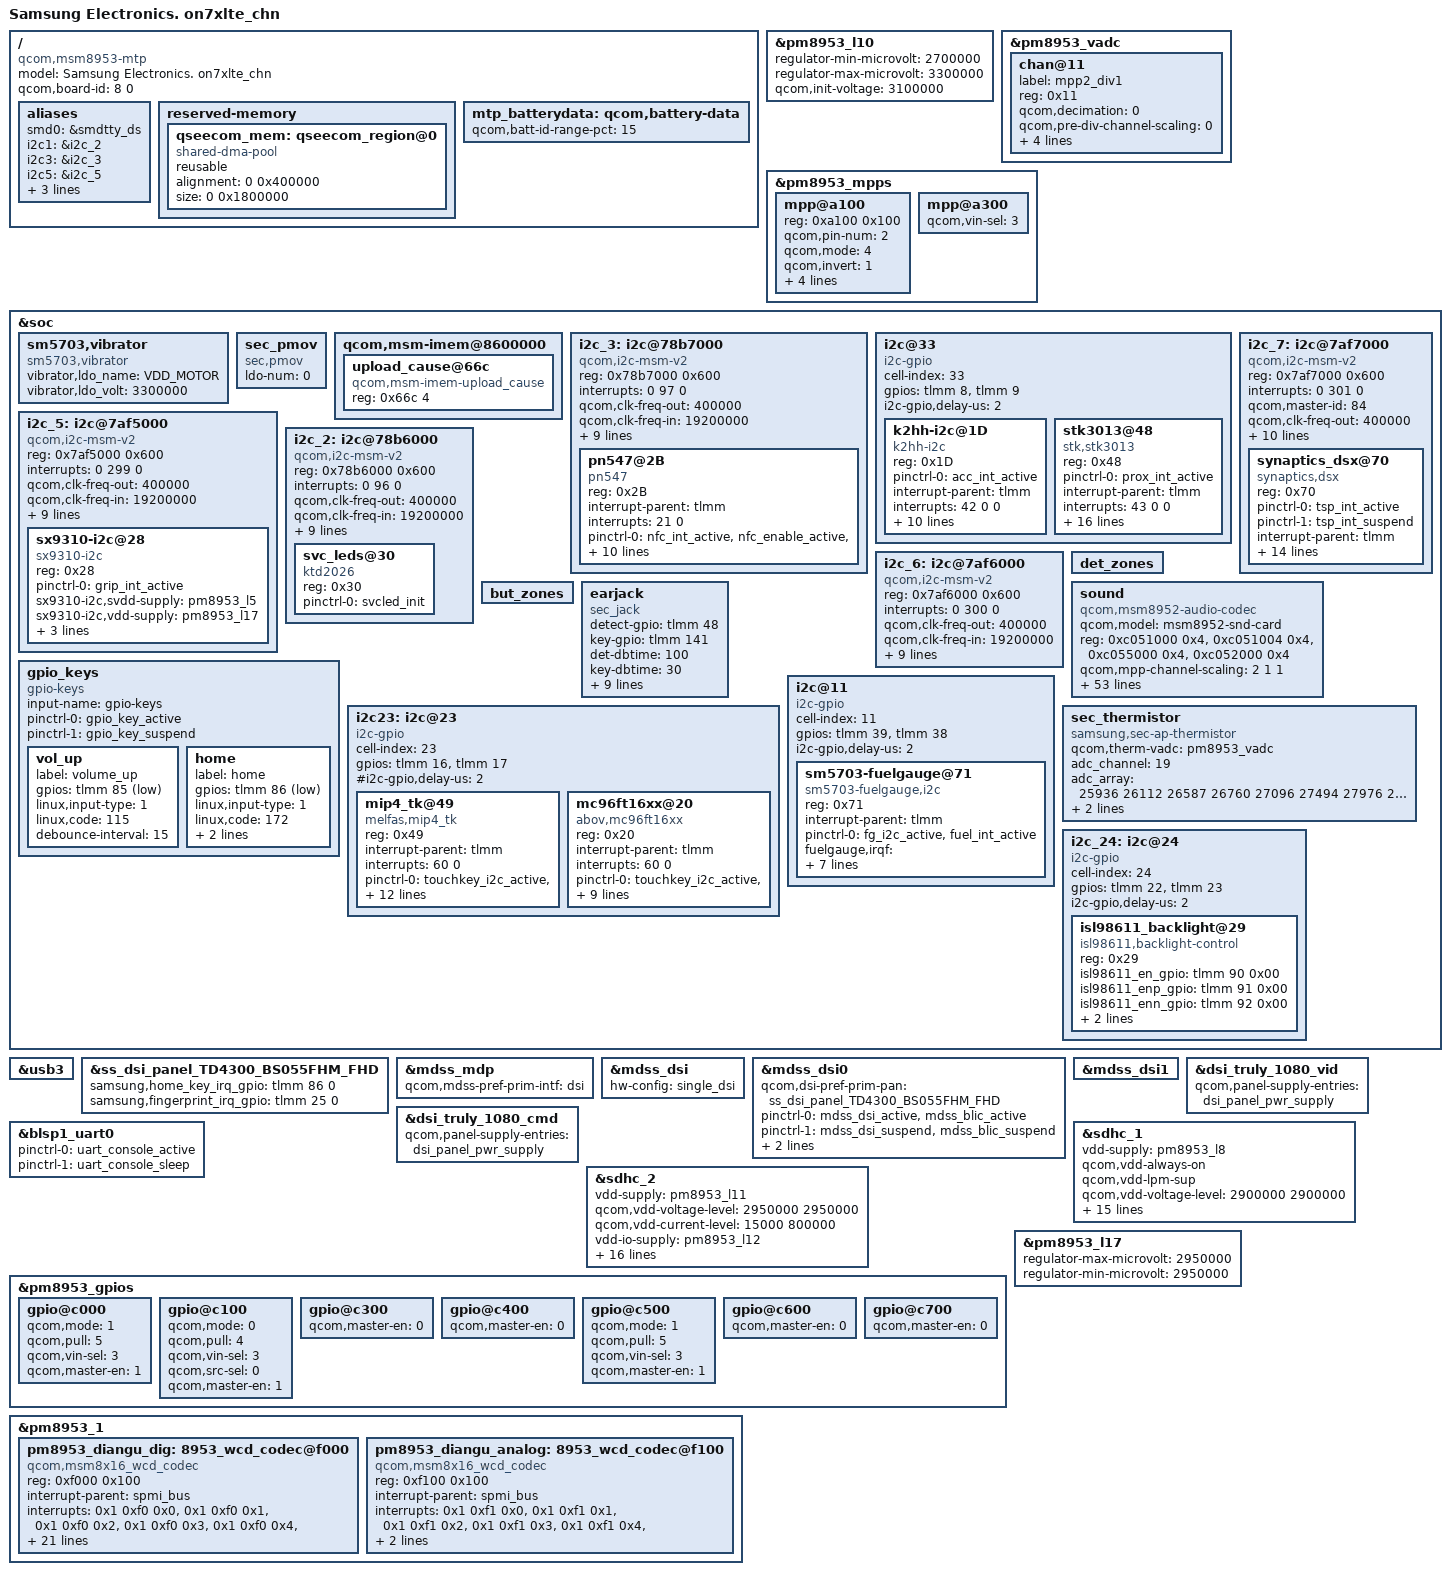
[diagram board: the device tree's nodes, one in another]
/*
 * Copyright (c) 2015, The Linux Foundation. All rights reserved.
 *
 * This program is free software; you can redistribute it and/or modify
 * it under the terms of the GNU General Public License version 2 and
 * only version 2 as published by the Free Software Foundation.
 *
 * This program is distributed in the hope that it will be useful,
 * but WITHOUT ANY WARRANTY; without even the implied warranty of
 * MERCHANTABILITY or FITNESS FOR A PARTICULAR PURPOSE.  See the
 * GNU General Public License for more details.
 */

/dts-v1/;

#include "../../qcom/msm8953.dtsi"
#include "msm-sec-audio.dtsi"
#include "msm8953-sec-common.dtsi"
#include "msm8953-sec-on7xlte_chn-pinctrl-r00.dtsi"
#include "msm8953-sec-on7xlte_chn-battery-r00.dtsi"
#include "msm8953-sec-on7xlte-chn-fingerprint-sensor_00.dtsi"
#include "msm8953-camera-sensor-on7-chn-r00.dtsi"
#include "msm8953-on7xlte-sm5703.dtsi"
#include "../../../../../../drivers/video/msm/mdss/samsung/TD4300_BS055FHM/dsi_panel_TD4300_BS055FHM_fhd_video.dtsi"
#include "../../../../../../drivers/video/msm/mdss/samsung/PBA_BOOTING_HD/dsi_panel_PBA_BOOTING_hd_video.dtsi"
/ {
	model = "Samsung Electronics. on7xlte_chn";
	compatible = "qcom,msm8953-mtp", "qcom,msm8953", "qcom,mtp";
	qcom,board-id= <8 0>;
	aliases {
		/delete-property/ spi3;
		/delete-property/ i2c2;
		smd0 = &smdtty_ds;
		i2c1 = &i2c_2; //SVC i2C
		i2c3 = &i2c_3; //NFC i2c
		i2c5 = &i2c_5; //Grip i2c
		i2c6 = &i2c_6; //LCD_BL i2c
		i2c7 = &i2c_7; //TSP i2c
		i2c8 = &i2c_8;
	};

	reserved-memory {
		/delete-node/ qseecom_region@0;
		qseecom_mem: qseecom_region@0 {
			compatible = "shared-dma-pool";
			reusable;
			alignment = <0 0x400000>;
			size = <0 0x1800000>;
		};
	};
};

&pm8953_l10 {
	status = "okay";
	regulator-min-microvolt = <2700000>;
	regulator-max-microvolt = <3300000>;
	qcom,init-voltage = <3100000>;
};

&pm8953_vadc {
	chan@11 {
		label = "mpp2_div1";
		reg = <0x11>;
		qcom,decimation = <0>;
		qcom,pre-div-channel-scaling = <0>;
		qcom,calibration-type = "absolute";
		qcom,scale-function = <0>;
		qcom,hw-settle-time = <5>;
		qcom,fast-avg-setup = <0>;
	};
};

&pm8953_mpps {
	mpp@a100 {
		reg = <0xa100 0x100>;
		qcom,pin-num = <2>;
		status = "okay";
		qcom,mode = <4>; /* AIN input */
		qcom,invert = <1>; /* Enable MPP */
		qcom,ain-route = <1>; /* AMUX 6 */
		qcom,master-en = <1>;
		qcom,src-sel = <0>; /* Function constant */
		qcom,vin-sel = <3>;
	};
	mpp@a300 {
		qcom,vin-sel = <3>;
		status = "okay";
	};
};

&soc {
	sm5703,vibrator {
		compatible = "sm5703,vibrator";
		vibrator,ldo_name = "VDD_MOTOR";
		vibrator,ldo_volt = <3300000>;
		status = "ok";
	};
	sec_pmov {
		compatible = "sec,pmov";

		/* pinctrl-names = "default";
		pinctrl-0 = <&nc_gpio_default>; */

		ldo-num = <0>;
		/*ldo0-supply = <&pm8953_l17>;
		 ldo1-supply = <&pm8953_lx>; */
	};

	qcom,msm-imem@8600000 {
		upload_cause@66c { /* CONFIG_SEC_DEBUG */
			compatible = "qcom,msm-imem-upload_cause";
			reg = <0x66c 4>;
		};
	};

	i2c_3: i2c@78b7000 { /* BLSP1 QUP3 */
		compatible = "qcom,i2c-msm-v2";
		#address-cells = <1>;
		#size-cells = <0>;
		reg-names = "qup_phys_addr";
		reg = <0x78b7000 0x600>;
		interrupt-names = "qup_irq";
		interrupts = <0 97 0>;
		qcom,clk-freq-out = <400000>;
		qcom,clk-freq-in  = <19200000>;
		clock-names = "iface_clk", "core_clk";
		clocks = <&clock_gcc clk_gcc_blsp1_ahb_clk>,
			<&clock_gcc clk_gcc_blsp1_qup3_i2c_apps_clk>;

		pinctrl-names = "i2c_active", "i2c_sleep";
		pinctrl-0 = <&i2c_3_active>;
		pinctrl-1 = <&i2c_3_sleep>;
		qcom,noise-rjct-scl = <0>;
		qcom,noise-rjct-sda = <0>;
		qcom,master-id = <86>;
		dmas = <&dma_blsp1 8 64 0x20000020 0x20>,
			<&dma_blsp1 9 32 0x20000020 0x20>;
		dma-names = "tx", "rx";
		status = "okay";

		pn547@2B {
			compatible = "pn547";
			reg = <0x2B>;
			interrupt-parent = <&tlmm>;
			interrupts = <21 0>;
			pinctrl-names = "default","sleep";
			pinctrl-0 = <&nfc_int_active &nfc_enable_active &nfc_pwr_req_active>;
			pinctrl-1 = <&nfc_int_suspend &nfc_enable_suspend>;
			pn547,ven-gpio = <&tlmm 93 0x0>;
			pn547,firm-gpio = <&tlmm 95 0x0>;
			pn547,irq-gpio = <&tlmm 21 0x00>;
			pn547,pwr_req = <&tlmm 97 0x00>;
			pn547,pvdd-gpio = <&tlmm 96 0x01>;
			/*pn547,clk_req-gpio = <&pm8950_gpios 2 0x00>;*/

			pn547,nfc_pm_clk;
			qcom,clk-src="BBCLK2";
			clocks = <&clock_gcc clk_bb_clk2_pin>;
			clock-names = "rf_clk";
		};
	};

	i2c@33 {
		cell-index = <33>;
		compatible = "i2c-gpio";
		gpios = <&tlmm 8 0	/* sda */
			&tlmm 9 0	/* scl */
			>;
		i2c-gpio,delay-us = <2>;
		#address-cells = <1>;
		#size-cells = <0>;

		k2hh-i2c@1D {
			compatible = "k2hh-i2c";
			reg = <0x1D>;
			pinctrl-names = "default";
			pinctrl-0 = <&acc_int_active>;
			interrupt-parent = <&tlmm>;
			interrupts = <42 0 0>;
			k2hh,irq_gpio = <&tlmm 42 0>;
			k2hh,vio-supply = <&pm8953_l5>;
			k2hh,axis_map_x = <0>;
			k2hh,axis_map_y = <1>;
			k2hh,axis_map_z = <2>;
			k2hh,negate_x = <1>;
			k2hh,negate_y = <0>;
			k2hh,negate_z = <0>;
			k2hh,poll_interval = <100>;
			k2hh,min_interval = <2>;
		};

		stk3013@48 {
			compatible = "stk,stk3013";
			reg = <0x48>;
			pinctrl-names = "default";
			pinctrl-0 = <&prox_int_active>;
			interrupt-parent =  <&tlmm>;
			interrupts = <43 0 0>;
			stk,vdd-supply = <&pm8953_l17>;
			stk,vio-supply = <&pm8953_l5>;
			stk,irq-gpio = <&tlmm 43 0>;
			stk,state-reg = <0x2d>;
			stk,psctrl-reg = <0x70>;
			stk,alsctrl-reg = <0x2A>;
			stk,ledctrl-reg = <0xF8>;
			stk,wait-reg = <0x03>;
			stk,ps-thd-h = <20>;
			stk,ps-thd-l = <13>;
			stk,ps-cancel-thd-h = <9>;
			stk,ps-cancel-thd-l = <6>;
			stk,ps-cal-skip-adc = <8>;
			stk,ps-cal-fail-adc = <17>;
			stk,ps-default-offset = <0>;
			stk,transmittance = <500>;
		};

	};

	i2c_5: i2c@7af5000 { /* BLSP2 QUP1 */
		compatible = "qcom,i2c-msm-v2";
		#address-cells = <1>;
		#size-cells = <0>;
		reg-names = "qup_phys_addr";
		reg = <0x7af5000 0x600>;
		interrupt-names = "qup_irq";
		interrupts = <0 299 0>;
		qcom,clk-freq-out = <400000>;
		qcom,clk-freq-in  = <19200000>;
		clock-names = "iface_clk", "core_clk";
		clocks = <&clock_gcc clk_gcc_blsp2_ahb_clk>,
			<&clock_gcc clk_gcc_blsp2_qup1_i2c_apps_clk>;

		pinctrl-names = "i2c_active", "i2c_sleep";
		pinctrl-0 = <&i2c_5_active>;
		pinctrl-1 = <&i2c_5_sleep>;
		qcom,noise-rjct-scl = <0>;
		qcom,noise-rjct-sda = <0>;
		qcom,master-id = <84>;
		dmas = <&dma_blsp2 4 64 0x20000020 0x20>,
			<&dma_blsp2 5 32 0x20000020 0x20>;
		dma-names = "tx", "rx";
		sx9310-i2c@28 {
			compatible = "sx9310-i2c";
			reg = <0x28>;
			pinctrl-names = "grip_int_active","grip_int_suspend";
			pinctrl-0 = <&grip_int_active>;
			sx9310-i2c,svdd-supply = <&pm8953_l5>;
			sx9310-i2c,vdd-supply = <&pm8953_l17>;
			interrupt-parent = <&tlmm>;
			interrupts = <44 0>;
			sx9310-i2c,nirq-gpio = <&tlmm 44 0x00>;
		};

	};

	i2c_7: i2c@7af7000 { /* BLSP2 QUP3 */
		compatible = "qcom,i2c-msm-v2";
		#address-cells = <1>;
		#size-cells = <0>;
		reg-names = "qup_phys_addr";
		reg = <0x7af7000 0x600>;
		interrupt-names = "qup_irq";
		interrupts = <0 301 0>;
		qcom,master-id = <84>;
		qcom,clk-freq-out = <400000>;
		qcom,clk-freq-in  = <19200000>;
		clock-names = "iface_clk", "core_clk";
		clocks = <&clock_gcc clk_gcc_blsp2_ahb_clk>,
			<&clock_gcc clk_gcc_blsp2_qup3_i2c_apps_clk>;
		pinctrl-names = "i2c_active", "i2c_sleep";
		pinctrl-0 = <&i2c_7_active>;
		pinctrl-1 = <&i2c_7_suspend>;
		qcom,noise-rjct-scl = <0>;
		qcom,noise-rjct-sda = <0>;
		qcom,disable-dma;
		dmas = <&dma_blsp2 8 64 0x20000020 0x20>,
			<&dma_blsp2 9 32 0x20000020 0x20>;
		dma-names = "tx", "rx";
	};

	/delete-node/i2c@78b6000;

	i2c_2: i2c@78b6000 { /* BLSP1 QUP2 */
		compatible = "qcom,i2c-msm-v2";
		#address-cells = <1>;
		#size-cells = <0>;
		reg-names = "qup_phys_addr";
		reg = <0x78b6000 0x600>;
		interrupt-names = "qup_irq";
		interrupts = <0 96 0>;
		qcom,clk-freq-out = <400000>;
		qcom,clk-freq-in  = <19200000>;
		clock-names = "iface_clk", "core_clk";
		clocks = <&clock_gcc clk_gcc_blsp1_ahb_clk>,
			<&clock_gcc clk_gcc_blsp1_qup2_i2c_apps_clk>;

		pinctrl-names = "i2c_active", "i2c_sleep";
		pinctrl-0 = <&i2c_2_active>;
		pinctrl-1 = <&i2c_2_sleep>;
		qcom,noise-rjct-scl = <0>;
		qcom,noise-rjct-sda = <0>;
		qcom,master-id = <86>;
		dmas = <&dma_blsp1 6 64 0x20000020 0x20>,
			<&dma_blsp1 7 32 0x20000020 0x20>;
		dma-names = "tx", "rx";
		svc_leds@30{
			compatible = "ktd2026";
			reg = <0x30>;
			pinctrl-names = "default";
			pinctrl-0 = <&svcled_init>;
		};

	};

	i2c_6: i2c@7af6000 { /* BLSP2 QUP2 */
		compatible = "qcom,i2c-msm-v2";
		#address-cells = <1>;
		#size-cells = <0>;
		reg-names = "qup_phys_addr";
		reg = <0x7af6000 0x600>;
		interrupt-names = "qup_irq";
		interrupts = <0 300 0>;
		qcom,clk-freq-out = <400000>;
		qcom,clk-freq-in  = <19200000>;
		clock-names = "iface_clk", "core_clk";
		clocks = <&clock_gcc clk_gcc_blsp2_ahb_clk>,
			<&clock_gcc clk_gcc_blsp2_qup2_i2c_apps_clk>;
		pinctrl-names = "i2c_active", "i2c_sleep";
		pinctrl-0 = <&i2c_6_active>;
		pinctrl-1 = <&i2c_6_sleep>;
		qcom,noise-rjct-scl = <0>;
		qcom,noise-rjct-sda = <0>;
		qcom,master-id = <84>;
		dmas = <&dma_blsp2 6 64 0x20000020 0x20>,
			<&dma_blsp2 7 32 0x20000020 0x20>;
		dma-names = "tx", "rx";
	};

	det_zones: det_zones {
		#list-det-cells = <4>;
	};

	but_zones: but_zones {
		#list-but-cells = <3>;
	};

	earjack {
		compatible = "sec_jack";
		detect-gpio = <&tlmm 48 0x0>;
		key-gpio = <&tlmm 141 0x0>;
		det-dbtime = <100>;
		key-dbtime = <30>;

		det-zones-list = <&det_zones 0 10000 10 2>,
				 <&det_zones 900 10000 10 2>,
				 <&det_zones 901 10000 10 1>,
				 <&det_zones 9999 10000 10 1>;
		but-zones-list = <&but_zones 226 0 186>, /* KEY_MEDIA:226 */
				 <&but_zones 582 187 229>, /* KEY_VOICECOMMAND:582 */
				 <&but_zones 115 230 343>, /* KEY_VOLUMEUP:115 */
				 <&but_zones 114 344 999>; /* KEY_VOLUMEDOWN:114 */

		pinctrl-names = "earjack_gpio_active",
				"earjack_gpio_suspend";
		pinctrl-0 = <&earjack_det_act &earjack_switch_act>;
		pinctrl-1 = <&earjack_det_sus &earjack_switch_sus>;
	};

	sound {
		compatible = "qcom,msm8952-audio-codec";
		qcom,model = "msm8952-snd-card";
		reg = <0xc051000 0x4>,
		      <0xc051004 0x4>,
		      <0xc055000 0x4>,
		      <0xc052000 0x4>;
		reg-names = "csr_gp_io_mux_mic_ctl",
			    "csr_gp_io_mux_spkr_ctl",
			    "csr_gp_io_lpaif_pri_pcm_pri_mode_muxsel",
			    "csr_gp_io_mux_quin_ctl";

		qcom,mpp-channel-scaling = <2 1 1>;
		qcom,earjack-read-vadc = <&pm8953_vadc>;
		qcom,msm-micbias1-ext-cap;
		qcom,msm-micbias2-ext-cap;
		qcom,msm-ext-pa = "primary";
		qcom,msm-mclk-freq = <9600000>;
		qcom,codec_ear_bias = <0>;
		qcom,msm-hs-micbias-type = "internal";
		qcom,audio-routing =
			"RX_BIAS", "MCLK",
			"SPK_RX_BIAS", "MCLK",
			"INT_LDO_H", "MCLK",
			"MIC BIAS External", "Handset Mic",
			"MIC BIAS External", "Secondary Mic",
			"AMIC1", "MIC BIAS External",
			"AMIC2", "Headset Mic",
			"AMIC3", "MIC BIAS External";
		qcom,msm-gpios =
			"pri_i2s",
			"comp_gpio";
		qcom,pinctrl-names =
			"all_off",
			"pri_i2s_act",
			"comp_gpio_act",
			"pri_i2s_comp_gpio_act";
		pinctrl-names =
			"all_off",
			"pri_i2s_act",
			"comp_gpio_act",
			"pri_i2s_comp_gpio_act";
		pinctrl-0 = <&cdc_pdm_lines_sus &cdc_pdm_comp_lines_sus &cdc_pdm_lines_2_sus >;
		pinctrl-1 = <&cdc_pdm_lines_act &cdc_pdm_comp_lines_sus &cdc_pdm_lines_2_act >;
		pinctrl-2 = <&cdc_pdm_lines_sus &cdc_pdm_comp_lines_act &cdc_pdm_lines_2_sus >;
		pinctrl-3 = <&cdc_pdm_lines_act &cdc_pdm_comp_lines_act &cdc_pdm_lines_2_act >;
		asoc-platform = <&pcm0>, <&pcm1>, <&pcm2>, <&voip>, <&voice>,
				<&loopback>, <&compress>, <&hostless>,
				<&afe>, <&lsm>, <&routing>, <&lpa>;
		asoc-platform-names = "msm-pcm-dsp.0", "msm-pcm-dsp.1",
				"msm-pcm-dsp.2", "msm-voip-dsp",
				"msm-pcm-voice", "msm-pcm-loopback",
				"msm-compress-dsp", "msm-pcm-hostless",
				"msm-pcm-afe", "msm-lsm-client",
				"msm-pcm-routing", "msm-pcm-lpa";
		asoc-cpu = <&dai_pri_auxpcm>,
				<&dai_mi2s0>, <&dai_mi2s1>,
				<&dai_mi2s2>, <&dai_mi2s3>,
				<&dai_mi2s5>, <&dai_mi2s6>,
				<&bt_sco_rx>, <&bt_sco_tx>,
				<&int_fm_rx>, <&int_fm_tx>,
				<&afe_pcm_rx>, <&afe_pcm_tx>,
				<&afe_proxy_rx>, <&afe_proxy_tx>,
				<&incall_record_rx>, <&incall_record_tx>,
				<&incall_music_rx>, <&incall_music_2_rx>;
		asoc-cpu-names = "msm-dai-q6-auxpcm.1",
				"msm-dai-q6-mi2s.0", "msm-dai-q6-mi2s.1",
				"msm-dai-q6-mi2s.2", "msm-dai-q6-mi2s.3",
				"msm-dai-q6-mi2s.5", "msm-dai-q6-mi2s.6",
				"msm-dai-q6-dev.12288", "msm-dai-q6-dev.12289",
				"msm-dai-q6-dev.12292", "msm-dai-q6-dev.12293",
				"msm-dai-q6-dev.224", "msm-dai-q6-dev.225",
				"msm-dai-q6-dev.241", "msm-dai-q6-dev.240",
				"msm-dai-q6-dev.32771", "msm-dai-q6-dev.32772",
				"msm-dai-q6-dev.32773", "msm-dai-q6-dev.32770";
		asoc-codec = <&stub_codec>, <&pm8953_diangu_dig>;
		asoc-codec-names = "msm-stub-codec.1", "cajon_codec";
	};

	gpio_keys {
		compatible = "gpio-keys";
		input-name = "gpio-keys";
		pinctrl-names = "tlmm_gpio_key_active","tlmm_gpio_key_suspend";
		pinctrl-0 = <&gpio_key_active>;
		pinctrl-1 = <&gpio_key_suspend>;

		vol_up {
			label = "volume_up";
			gpios = <&tlmm 85 0x1>;
			linux,input-type = <1>;
			linux,code = <115>;
			debounce-interval = <15>;
		};

		home {
			label = "home";
			gpios = <&tlmm 86 0x1>;
			linux,input-type = <1>;
			linux,code = <172>;
			gpio-key,wakeup;
			debounce-interval = <15>;
		};
	};

	i2c23: i2c@23 { /* SW I2C */
		cell-index = <23>;
		compatible = "i2c-gpio";
		gpios = <&tlmm 16 0 /* sda */
			&tlmm 17 0 /* scl */
		>;
		#i2c-gpio,delay-us = <2>;
		#address-cells = <1>;
		#size-cells = <0>;

		mip4_tk@49{
			compatible = "melfas,mip4_tk";
			reg = <0x49>;
			interrupt-parent = <&tlmm>;
			interrupts = <60 0>;
			pinctrl-names = "touchkey_active", "touchkey_suspend";
			pinctrl-0 = <&touchkey_i2c_active &touchkey_int_active>;
			pinctrl-1 = <&touchkey_i2c_suspend &touchkey_int_suspend>;
			mip4_tk,keynum = <2>;
			mip4_tk,keycode = <254 158>;
			mip4_tk,sda-gpio = <&tlmm 16 0>;
			mip4_tk,scl-gpio = <&tlmm 17 0>;
			mip4_tk,irq-gpio = <&tlmm 60 0>;
			mip4_tk,pwr-reg-name = "pwr";
			//mip4_tk,bus-reg-name = "bus";
			//bus-supply = <&pm8953_l6>;
			pwr-supply = <&pm8953_l10>;
			mip4_tk,firmware-name = "tk_melfas/mhs204_on7xlte.fw";
		};

		mc96ft16xx@20{
			compatible = "abov,mc96ft16xx";
			reg = <0x20>;
			interrupt-parent = <&tlmm>;
			interrupts = <60 0>;
			pinctrl-names = "touchkey_active", "touchkey_suspend";
			pinctrl-0 = <&touchkey_i2c_active &touchkey_int_active>;
			pinctrl-1 = <&touchkey_i2c_suspend &touchkey_int_suspend>;
			abov,sda-gpio = <&tlmm 16 0>;
			abov,scl-gpio = <&tlmm 17 0>;
			abov,irq-gpio = <&tlmm 60 0>;
			abov,tkey_en-gpio = <&tlmm 132 0>;
			abov,firmware_name = "abov/abov_tk_1604_c7.fw";
			//abov,tkey_led_en-gpio = <&tlmm 91 0>;
			vddo-supply = <&pm8953_l6>;
		};
	};

	i2c@11 {
		cell-index = <11>;
		compatible = "i2c-gpio";
		gpios = <&tlmm 39 0	/* sda */
			&tlmm 38 0	/* scl */
			>;
		i2c-gpio,delay-us = <2>;
		#address-cells = <1>;
		#size-cells = <0>;

		sm5703-fuelgauge@71{
			compatible = "sm5703-fuelgauge,i2c";
			reg = <0x71>;
			interrupt-parent = <&tlmm>;
			pinctrl-names = "default";
			pinctrl-0 = <&fg_i2c_active &fuel_int_active>;
			fuelgauge,irqf = "IRQF_TRIGGER_FALLING + IRQF_ONESHOT + IRQF_NO_SUSPEND";
			fuelgauge,fuel_int = <&tlmm 62 0x1>;
			fuelgauge,fuel_alert_soc = <1>;
			fuelgauge,capacity_max = <1000>;
			fuelgauge,capacity_max_margin = <70>;
			fuelgauge,capacity_min = <0>;
			fuelgauge,capacity_calculation_type = <0x1F>;
		};
	};

	sec_thermistor {
		compatible = "samsung,sec-ap-thermistor";
		qcom,therm-vadc = <&pm8953_vadc>;
		status = "okay";
		adc_channel = <19>;
		adc_array = <25936 26112 26587 26760 27096 27494 27976 28081
                                         28185 28306 28433 28538 28664 28797 28956 29121
                                         29243 29391 29564 29760 29823 29974 30175 30299
                                         30467 30642 30787 30997 31170 31355 31561 31752
                                         31944 32145 32326 32569 32745 32949 33141 33372
                                         33573 33790 33974 34190 34432 34659 34874 35067
                                         35303 35524 35726 35940 36123 36303 36555 36784
                                         36974 37162 37386 37621 37704 37965 38154 38321
                                         38475 38649 38799 39048 39160 39318 39490 39640
                                         39780 39907 40045 40170 40306 40433 40534 40575
                                         40732 40786 40823 40872 40900 40977 41140 41612
                                         41965>;

		temp_array = <900 850 800 750 700 650 600 590 580 570
			560 550 540 530 520 510 500 490 480 470
			460 450 440 430 420 410 400 390 380 370
			360 350 340 330 320 310 300 290 280 270
			260 250 240 230 220 210 200 190 180 170
			160 150 140 130 120 110 100 90 80 70
			60 50 40 30 20 10 0 (-10) (-20) (-30)
			(-40) (-50) (-60) (-70) (-80) (-90) (-100) (-110) (-120) (-130)
			(-140) (-150) (-160) (-170) (-180) (-190) (-200) (-250) (-300)>;
	};

};

&usb3 {
	/delete-property/ vbus_dwc3-supply;
};

&i2c_7 {
	status = "ok";
	synaptics_dsx@70 {
		compatible = "synaptics,dsx";
		reg = <0x70>;
		pinctrl-names = "on_state", "off_state";
		pinctrl-0 = <&tsp_int_active>;
		pinctrl-1 = <&tsp_int_suspend>;
		interrupt-parent = <&tlmm>;
		interrupts = <59 0>;
		synaptics,irq_gpio = <&tlmm 59 0>;
		synaptics,irq_type = <8200>;
		synaptics,max_coords = <1080 1920>;
		synaptics,num_lines = <30 18>;
		synaptics,project_name = "On7x", "G6100";
		synaptics,ub-i2c-addr = <0x2c>;
		synaptics,reset-delay-ms = <150>;
		synaptics,firmware_name = "tsp_synaptics/td4300_on7xlte.fw";
		synaptics,firmware_name_bl = "tsp_synaptics/td4300_on7xlte_recovery.fw";
		clock-names = "iface_clk", "core_clk";
		clocks = <&clock_gcc clk_gcc_blsp1_ahb_clk>,
			<&clock_gcc clk_gcc_blsp1_qup3_i2c_apps_clk>;
	};
};



#include "../../qcom/msm8953-mdss-panels.dtsi"

&ss_dsi_panel_TD4300_BS055FHM_FHD{

	/* reduce display on time */
	samsung,home_key_irq_gpio = <&tlmm 86 0>;
	samsung,fingerprint_irq_gpio = <&tlmm 25 0>;
};

&mdss_mdp {
	qcom,mdss-pref-prim-intf = "dsi";
};

&mdss_dsi {
	hw-config = "single_dsi";
};

&mdss_dsi0 {
	/delete-property/ lab-supply;
	/delete-property/ ibb-supply;
	qcom,dsi-pref-prim-pan = <&ss_dsi_panel_TD4300_BS055FHM_FHD>;
	pinctrl-names = "mdss_default", "mdss_sleep";
	pinctrl-0 = <&mdss_dsi_active &mdss_blic_active>;
	pinctrl-1 = <&mdss_dsi_suspend &mdss_blic_suspend>;

	qcom,platform-reset-gpio = <&tlmm 50 0>;
	qcom,platform-enable-gpio = <&tlmm 94 0>;
};

&mdss_dsi1 {
	/delete-property/ lab-supply;
	/delete-property/ ibb-supply;
};

&soc {
	i2c_24: i2c@24 {

		cell-index = <24>;
		compatible = "i2c-gpio";
		gpios = <&tlmm 22 0 /* sda */
			&tlmm 23 0 /* scl */
			>;
		i2c-gpio,delay-us = <2>;
		#address-cells = <1>;
		#size-cells = <0>;

		isl98611_backlight@29 {
			compatible = "isl98611,backlight-control";
			reg = <0x29>;

			isl98611_en_gpio = <&tlmm 90 0x00>;
			isl98611_enp_gpio = <&tlmm 91 0x00>;
			isl98611_enn_gpio = <&tlmm 92 0x00>;

			blic_init_data = [
				01		00
				02		BF
				03		02
				04		0A
				05		0A
				06		F4
				10		FF
				11		07
				12		BF
				13		80
				14		FD
				16		F5
				17		8D
			];
		};
	};
};

&dsi_truly_1080_vid {
	qcom,panel-supply-entries = <&dsi_panel_pwr_supply>;
};

&dsi_truly_1080_cmd {
	qcom,panel-supply-entries = <&dsi_panel_pwr_supply>;
};

&blsp1_uart0 {
	status = "ok";
	pinctrl-names = "default";
	pinctrl-0 = <&uart_console_active>;
	pinctrl-1 = <&uart_console_sleep>;
};

&sdhc_1 {
	/* device core power supply */
	vdd-supply = <&pm8953_l8>;
	qcom,vdd-always-on;
	qcom,vdd-lpm-sup;
	qcom,vdd-voltage-level = <2900000 2900000>;
	qcom,vdd-current-level = <200 570000>;

	/* device communication power supply */
	vdd-io-supply = <&pm8953_l5>;
	qcom,vdd-io-always-on;
	qcom,vdd-io-lpm-sup;
	qcom,vdd-io-voltage-level = <1800000 1800000>;
	qcom,vdd-io-current-level = <200 325000>;

	pinctrl-names = "active", "sleep";
	pinctrl-0 = <&sdc1_clk_on &sdc1_cmd_on &sdc1_data_on  &sdc1_rclk_on>;
	pinctrl-1 = <&sdc1_clk_off &sdc1_cmd_off &sdc1_data_off &sdc1_rclk_off>;

	qcom,clk-rates = <400000 20000000 25000000 50000000 100000000 192000000
								384000000>;
	qcom,nonremovable;
	qcom,bus-speed-mode = "HS400_1p8v", "HS200_1p8v", "DDR_1p8v";

	status = "ok";
};

&sdhc_2 {
	/* device core power supply */
	vdd-supply = <&pm8953_l11>;
	qcom,vdd-voltage-level = <2950000 2950000>;
	qcom,vdd-current-level = <15000 800000>;

	/* device communication power supply */
	vdd-io-supply = <&pm8953_l12>;
	qcom,vdd-io-voltage-level = <1800000 2950000>;
	qcom,vdd-io-current-level = <200 22000>;

	pinctrl-names = "active", "sleep";
	pinctrl-0 = <&sdc2_clk_on &sdc2_cmd_on &sdc2_data_on &sdc2_cd_on>;
	pinctrl-1 = <&sdc2_clk_off &sdc2_cmd_off &sdc2_data_off &sdc2_cd_off>;

	#address-cells = <0>;
	interrupt-parent = <&sdhc_2>;
	interrupts = <0 1 2>;
	#interrupt-cells = <1>;
	interrupt-map-mask = <0xffffffff>;
	interrupt-map = <0 &intc 0 125 0
		1 &intc 0 221 0
		2 &tlmm 133 0>;
	interrupt-names = "hc_irq", "pwr_irq", "status_irq";
	cd-gpios = <&tlmm 133 0x1>;

	qcom,clk-rates = <400000 20000000 25000000 50000000 100000000
								192000000>;
	qcom,bus-speed-mode = "SDR12", "SDR25", "SDR50", "DDR50", "SDR104";

	status = "ok";
};

/{
	mtp_batterydata: qcom,battery-data {
		qcom,batt-id-range-pct = <15>;
		#include "../../qcom/batterydata-itech-3000mah.dtsi"
		#include "../../qcom/batterydata-ascent-3450mAh.dtsi"
	};
};

&pm8953_gpios {
	/* GPIO 1*/
	gpio@c000 {
		qcom,mode = <1>;
		qcom,pull = <5>;
		qcom,vin-sel = <3>;	/* 1.8V*/
		qcom,master-en = <1>;
		status = "okay";
	};
	/* GPIO 2 (NFC_CLK_REQ) */
	gpio@c100 {
		qcom,mode = <0>;
		qcom,pull = <4>;
		qcom,vin-sel = <3>;	/* 1.8V*/
		qcom,src-sel = <0>; /*src-sel has no matter when mode is input*/
		qcom,master-en = <1>;
		status = "okay";
	};
	/* GPIO 4*/
	gpio@c300 {
		qcom,master-en = <0>;
		status = "okay";
	};
	/* GPIO 5*/
	gpio@c400 {
		qcom,master-en = <0>;
		status = "okay";
	};
	/* GPIO 6*/
	gpio@c500 {
		qcom,mode = <1>;
		qcom,pull = <5>;
		qcom,vin-sel = <3>;	/* 1.8V*/
		qcom,master-en = <1>;
		status = "okay";
	};
	/* GPIO 7 */
	gpio@c600 {
		qcom,master-en = <0>;
		status = "okay";
	};
	/* GPIO 8 */
	gpio@c700 {
		qcom,master-en = <0>;
		status = "okay";
	};
};

&pm8953_l17 {
    regulator-max-microvolt = <2950000>;
    regulator-min-microvolt = <2950000>;
};

&pm8953_1 {
	pm8953_diangu_dig: 8953_wcd_codec@f000 {
		compatible = "qcom,msm8x16_wcd_codec";
		reg = <0xf000 0x100>;
		interrupt-parent = <&spmi_bus>;
		interrupts = <0x1 0xf0 0x0>,
			     <0x1 0xf0 0x1>,
			     <0x1 0xf0 0x2>,
			     <0x1 0xf0 0x3>,
			     <0x1 0xf0 0x4>,
			     <0x1 0xf0 0x5>,
			     <0x1 0xf0 0x6>,
			     <0x1 0xf0 0x7>;
		interrupt-names = "spk_cnp_int",
				  "spk_clip_int",
				  "spk_ocp_int",
				  "ins_rem_det1",
				  "but_rel_det",
				  "but_press_det",
				  "ins_rem_det",
				  "mbhc_int";

		cdc-vdda-cp-supply = <&pm8953_s4>;
		qcom,cdc-vdda-cp-voltage = <1900000 2050000>;
		qcom,cdc-vdda-cp-current = <500000>;

		cdc-vdd-io-supply = <&pm8953_l5>;
		qcom,cdc-vdd-io-voltage = <1800000 1800000>;
		qcom,cdc-vdd-io-current = <5000>;

		cdc-vdd-pa-supply = <&pm8953_s4>;
		qcom,cdc-vdd-pa-voltage = <1900000 2050000>;
		qcom,cdc-vdd-pa-current = <260000>;

		cdc-vdd-mic-bias-supply = <&pm8953_l13>;
		qcom,cdc-vdd-mic-bias-voltage = <3125000 3125000>;
		qcom,cdc-vdd-mic-bias-current = <5000>;

		qcom,cdc-mclk-clk-rate = <9600000>;
		qcom,cdc-micbias-cfilt-mv = <2800000>;
		qcom,ext_pullup_imp;
		qcom,tx2n_to_hph_ref;
		qcom,cdc-static-supplies =  "cdc-vdd-io",
					   "cdc-vdd-pa",
					   "cdc-vdda-cp";

		qcom,cdc-on-demand-supplies = "cdc-vdd-mic-bias";
		qcom,dig-cdc-base-addr = <0xc0f0000>;
	};

	pm8953_diangu_analog: 8953_wcd_codec@f100 {
		compatible = "qcom,msm8x16_wcd_codec";
		reg = <0xf100 0x100>;
		interrupt-parent = <&spmi_bus>;
		interrupts = <0x1 0xf1 0x0>,
			     <0x1 0xf1 0x1>,
			     <0x1 0xf1 0x2>,
			     <0x1 0xf1 0x3>,
			     <0x1 0xf1 0x4>,
			     <0x1 0xf1 0x5>;
		interrupt-names = "ear_ocp_int",
				  "hphr_ocp_int",
				  "hphl_ocp_det",
				  "ear_cnp_int",
				  "hphr_cnp_int",
				  "hphl_cnp_int";
		qcom,dig-cdc-base-addr = <0xc0f0000>;
	};
};
